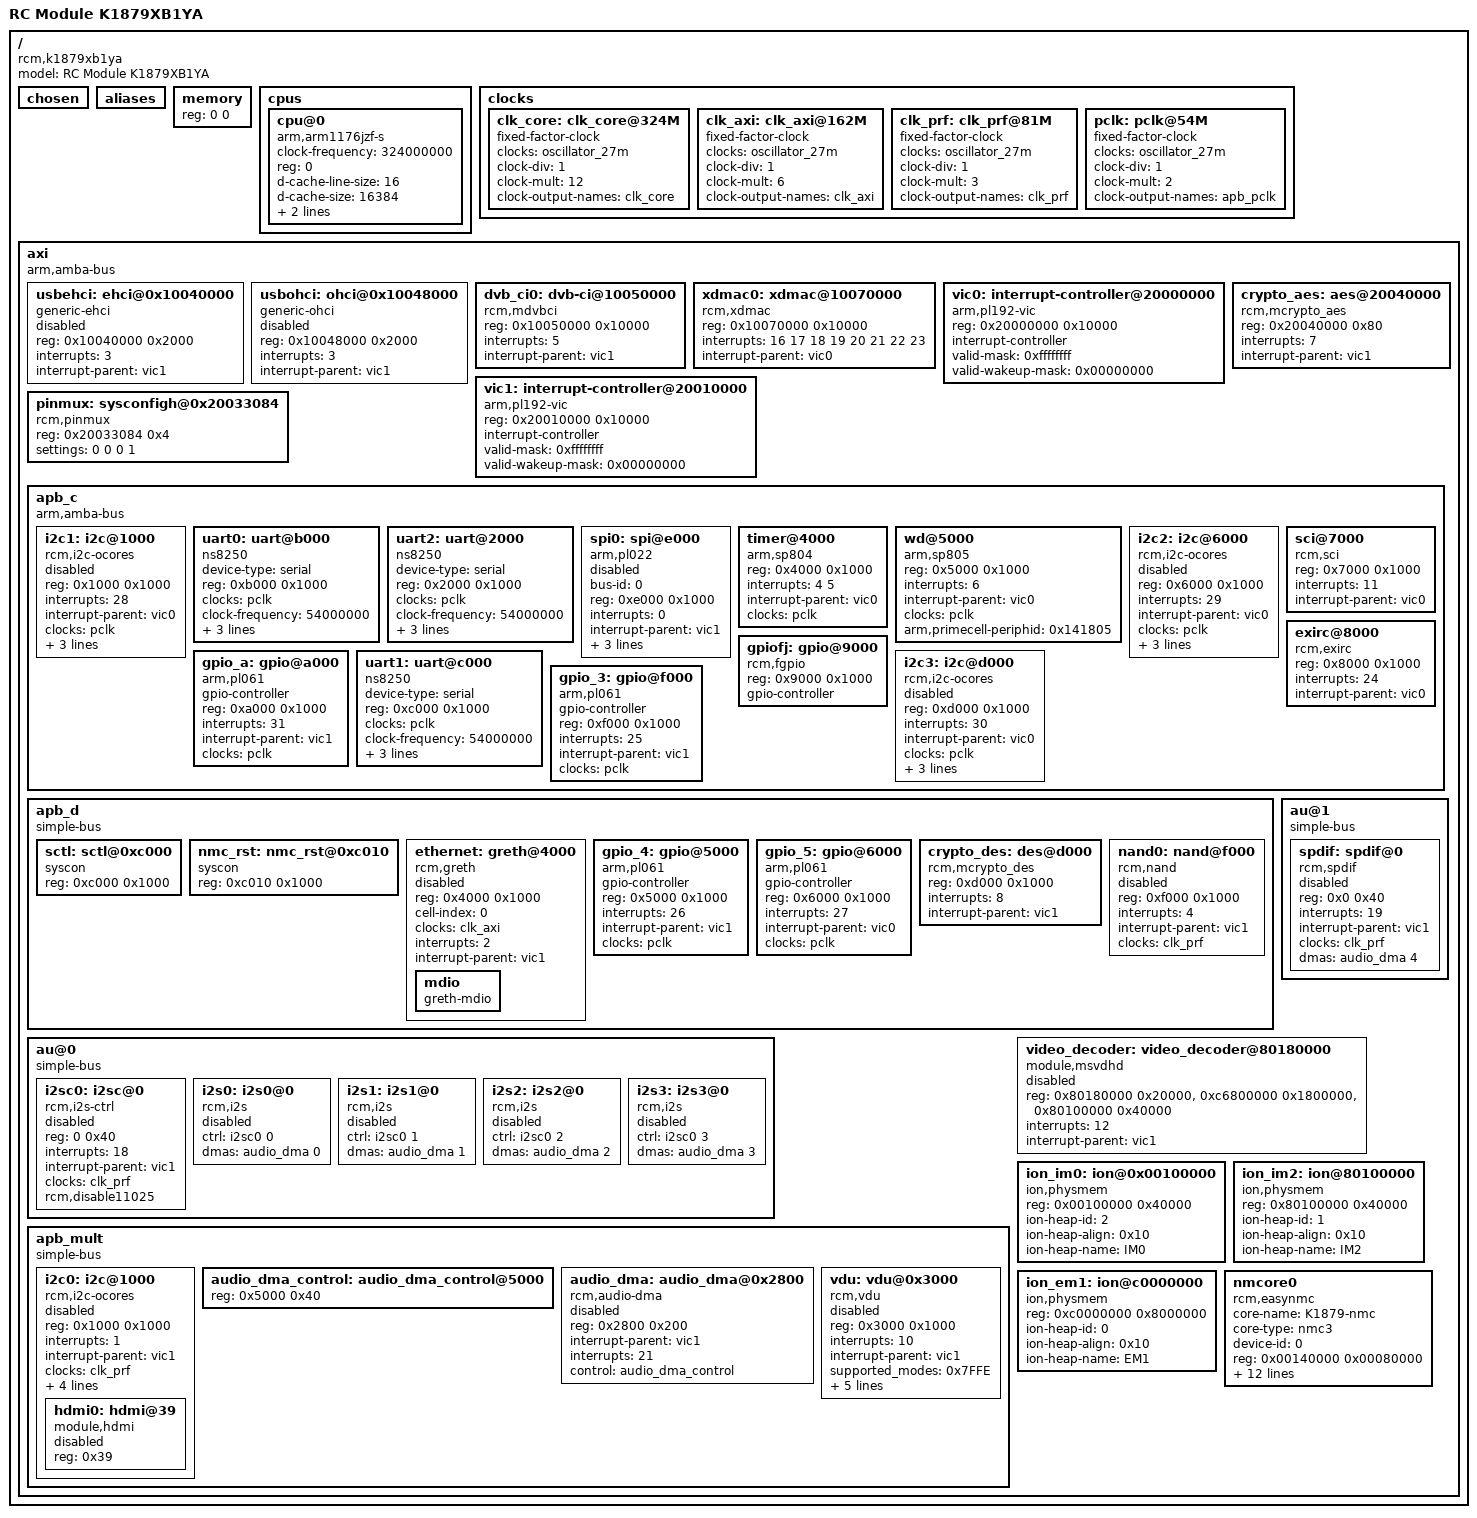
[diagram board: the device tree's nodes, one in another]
/*
 * Copyright Promwad inc 2011
 * Copyright RC Module 2010-2015
 *
 * Michail Kurachkin <stelhs@ya.ru>
 * Andrew Andrianov  <andrew@ncrmnt.org>
 *
 * This program is free software; you can redistribute it and/or modify
 * it under the terms of the GNU General Public License version 2 as
 * published by the Free Software Foundation.
 */

/ {

	model = "RC Module K1879XB1YA";
	compatible = "rcm,k1879xb1ya";

	#address-cells = <1>;
	#size-cells = <1>;
	chosen { };
	aliases { };
	memory { device_type = "memory"; reg = <0 0>; };

	cpus {
		#address-cells = <1>;
		#size-cells = <0>;
		cpu@0 {
			device_type = "cpu";
			compatible = "arm,arm1176jzf-s", "arm,arm1176";
			clock-frequency = <324000000>;
			reg = <0>;
			d-cache-line-size = <16>;
			d-cache-size = <16384>;
			i-cache-line-size = <16>;
			i-cache-size = <16384>;
		};
	};

	clocks {
			clk_core: clk_core@324M {
				/* Core 324MHz clock. */
				compatible = "fixed-factor-clock";
				#clock-cells = <0>;
				clocks = <&oscillator_27m>;
				clock-div = <1>;
				clock-mult = <12>;
				clock-output-names = "clk_core";
			};

			clk_axi: clk_axi@162M {
				/* 162MHz clock */
				compatible = "fixed-factor-clock";
				#clock-cells = <0>;
				clocks = <&oscillator_27m>;
				clock-div = <1>;
				clock-mult = <6>;
				clock-output-names = "clk_axi";
			};

			clk_prf: clk_prf@81M {
				/* 81MHz clock */
				compatible = "fixed-factor-clock";
				#clock-cells = <0>;
				clocks = <&oscillator_27m>;
				clock-div = <1>;
				clock-mult = <3>;
				clock-output-names = "clk_prf";
			};

			pclk: pclk@54M {
				/* Reference 54MHz clock */
				compatible = "fixed-factor-clock";
				#clock-cells = <0>;
				clocks = <&oscillator_27m>;
				clock-div = <1>;
				clock-mult = <2>;
				clock-output-names = "apb_pclk";
			};
	};

	axi {
		compatible = "arm,amba-bus";
		#address-cells = <1>;
		#size-cells = <1>;
		ranges = <0 0x0 0xFFFFFFFF>;

		usbehci: ehci@0x10040000 {
			compatible = "generic-ehci";
			reg = <0x10040000 0x2000>;
			interrupts = <3>; /* 35 */
			interrupt-parent = <&vic1>;
			status = "disabled";
		};

		usbohci: ohci@0x10048000 {
			compatible = "generic-ohci";
			reg = <0x10048000 0x2000>;
			interrupts = <3>; /* 35 */
			interrupt-parent = <&vic1>;
			status = "disabled";
		};

		dvb_ci0: dvb-ci@10050000 {
			compatible = "rcm,mdvbci";
			reg = <0x10050000 0x10000>;
			interrupts = <5>; /* 37 */
			interrupt-parent = <&vic1>;
		};

		xdmac0: xdmac@10070000 {
			compatible = "rcm,xdmac";
			reg = <0x10070000 0x10000>;
			interrupts = <16 17 18 19 20 21 22 23>;
			interrupt-parent = <&vic0>;
		};

		vic0: interrupt-controller@20000000 {
			reg = <0x20000000 0x10000>;
			compatible = "arm,pl192-vic";
			interrupt-controller;
			#interrupt-cells = <1>;
			valid-mask = <0xffffffff>;
			valid-wakeup-mask = <0x00000000>;
		};

		vic1: interrupt-controller@20010000 {
			reg = <0x20010000 0x10000>;
			compatible = "arm,pl192-vic";
			interrupt-controller;
			#interrupt-cells = <1>;
			valid-mask = <0xffffffff>;
			valid-wakeup-mask = <0x00000000>;
		};

		pinmux: sysconfigh@0x20033084 {
			compatible = "rcm,pinmux";
			reg = <0x20033084 0x4>;
			reg-names = "controlH";
			settings = <0 0 0 1>; // DVB, TS1, TS2, NAND; 0 = GPIO, 1 = peripheral
		};

		crypto_aes: aes@20040000 {
			compatible = "rcm,mcrypto_aes";
			reg = <0x20040000 0x80>;
			interrupts = <7>; /* 39 */
			interrupt-parent = <&vic1>;
		};

		apb_c {
			compatible = "arm,amba-bus", "simple-bus";
			#address-cells = <1>;
			#size-cells = <1>;
			ranges = <0 0x20020000 0x10000>;

			i2c1: i2c@1000 {
				#address-cells = <1>;
				#size-cells = <0>;
				reg = <0x1000 0x1000>;
				compatible = "rcm,i2c-ocores";
				interrupts = <28>;
				interrupt-parent = <&vic0>;
				clocks = <&pclk>;
				clock-names = "apb_pclk";
				clock-frequency = <54000000>;
				reg-shift = <2>;
				rcm-irq-fixup-id = <1>;
				status = "disabled";
			};

			uart0: uart@b000 {
				device-type = "serial";
				reg = <0xb000 0x1000>;
				compatible = "ns8250";
				clocks = <&pclk>;
				clock-names = "apb_pclk";
				clock-frequency = <54000000>;
				interrupts = <7>;
				interrupt-parent = <&vic0>;
				reg-shift = <2>;
			};

			uart2: uart@2000 {
				device-type = "serial";
				reg = <0x2000 0x1000>;
				compatible = "ns8250";
				clocks = <&pclk>;
				clock-names = "apb_pclk";
				clock-frequency = <54000000>;
				interrupts = <9>;
				interrupt-parent = <&vic0>;
				reg-shift = <2>;
			};

			spi0: spi@e000 {
				compatible = "arm,pl022", "arm,primecell";
				bus-id = <0>;
				reg = <0xe000 0x1000>;
				#address-cells = <1>;
				#size-cells = <0>;
				interrupts = <0>; /* 32 */
				interrupt-parent = <&vic1>;
				clocks = <&pclk>;
				clock-names = "apb_pclk";
				num-cs = <2>;
				status = "disabled";
				/* Silicon BUG: no periphid at 0xe000 reg */
				arm,primecell-periphid = <0x41022>;
			};

			timer@4000 {
				compatible = "arm,sp804", "arm,primecell";
				reg = <0x4000 0x1000>;
				interrupts = <4 5>;
				interrupt-parent = <&vic0>;
				interrupt-names = "timer0", "timer1";
				clocks = <&pclk>;
				clock-names = "apb_pclk";
			};

			wd@5000 {
				reg = <0x5000 0x1000>;
				compatible = "arm,sp805", "arm,primecell";
				interrupts = <6>;
				interrupt-parent = <&vic0>;
				clocks = <&pclk>;
				clock-names = "apb_pclk";
				arm,primecell-periphid = <0x141805>;
				status = "okay";
			};

			i2c2: i2c@6000 {
				#address-cells = <1>;
				#size-cells = <0>;
				reg = <0x6000 0x1000>;
				compatible = "rcm,i2c-ocores";
				interrupts = <29>;
				interrupt-parent = <&vic0>;
				clocks = <&pclk>;
				clock-names = "apb_pclk";
				clock-frequency = <54000000>;
				reg-shift = <2>;
				rcm-irq-fixup-id = <2>;
				status = "disabled";
			};

			sci@7000 {
				reg = <0x7000 0x1000>;
				compatible = "rcm,sci";
				interrupts = <11>;
				interrupt-parent = <&vic0>;
			};

			exirc@8000 {
				reg = <0x8000 0x1000>;
				compatible = "rcm,exirc";
				interrupts = <24>;
				interrupt-parent = <&vic0>;
			};

			gpiofj: gpio@9000 {
				#gpio-cells = <2>;
				reg = <0x9000 0x1000>;
				reg-names = "regs";
				gpio-controller;
				compatible = "rcm,fgpio";
			};

			gpio_a: gpio@a000 {
				#gpio-cells = <2>;
				compatible = "arm,pl061", "arm,primecell";
				gpio-controller;
				reg = <0xa000 0x1000>;
				interrupts = <31>; /* 63 */
				interrupt-parent = <&vic1>;
				clocks = <&pclk>;
				clock-names = "apb_pclk";
			};

			uart1: uart@c000 {
				device-type = "serial";
				reg = <0xc000 0x1000>;
				compatible = "ns8250";
				clocks = <&pclk>;
				clock-names = "apb_pclk";
				clock-frequency = <54000000>;
				interrupts = <8>;
				interrupt-parent = <&vic0>;
				reg-shift = <2>;
			};

			i2c3: i2c@d000 {
				#address-cells = <1>;
				#size-cells = <0>;
				reg = <0xd000 0x1000>;
				compatible = "rcm,i2c-ocores";
				interrupts = <30>;
				interrupt-parent = <&vic0>;
				clocks = <&pclk>;
				clock-names = "apb_pclk";
				clock-frequency = <54000000>;
				reg-shift = <2>;
				rcm-irq-fixup-id = <3>;
				status = "disabled";
			};

			gpio_3: gpio@f000 {
				#gpio-cells = <2>;
				compatible = "arm,pl061", "arm,primecell";
				gpio-controller;
				reg = <0xf000 0x1000>;
				interrupts = <25>; /* 57 */
				interrupt-parent = <&vic1>;
				clocks = <&pclk>;
				clock-names = "apb_pclk";
			};
		};

		apb_d {
			compatible = "simple-bus";
			#address-cells = <1>;
			#size-cells = <1>;
			ranges = <0 0x20030000 0x10000>;

			sctl: sctl@0xc000
			{
				compatible = "syscon";
				reg = <0xc000 0x1000>;
			};

			nmc_rst: nmc_rst@0xc010
			{
				compatible = "syscon";
				reg = <0xc010 0x1000>;
			};

			ethernet: greth@4000 {
				#address-cells = <1>;
				#size-cells = <1>;
				compatible = "rcm,greth";
				reg = <0x4000 0x1000>;
				cell-index = <0>;
				device_type = "network";
				clocks = <&clk_axi>;
				clock-names = "clk_axi";
				interrupts = <2>; /* 34 */
				interrupt-parent = <&vic1>;
				status = "disabled";

				mdio {
					compatible = "greth-mdio";
					#address-cells = <1>;
					#size-cells = <0>;
				};
			};

			gpio_4: gpio@5000 {
				#gpio-cells = <2>;
				compatible = "arm,pl061", "arm,primecell";
				gpio-controller;
				reg = <0x5000 0x1000>;
				interrupts = <26>; /* 58 */
				interrupt-parent = <&vic1>;
				clocks = <&pclk>;
				clock-names = "apb_pclk";
			};

			gpio_5: gpio@6000 {
				#gpio-cells = <2>;
				compatible = "arm,pl061", "arm,primecell";
				gpio-controller;
				reg = <0x6000 0x1000>;
				interrupts = <27>;
				interrupt-parent = <&vic0>;
				clocks = <&pclk>;
				clock-names = "apb_pclk";
			};

			crypto_des: des@d000 {
				compatible = "rcm,mcrypto_des";
				reg = <0xd000 0x1000>;
				interrupts = <8>; /* 40 */
				interrupt-parent = <&vic1>;
			};

			nand0: nand@f000 {
				reg = <0xf000 0x1000>;
				compatible = "rcm,nand";
				interrupts = <4>; /* 36 */
				interrupt-parent = <&vic1>;
				clocks = <&clk_prf>;
				clock-names = "clk_prf";
				status = "disabled";
			};
		};

		au@0 {
			compatible = "simple-bus";
			#address-cells = <1>;
			#size-cells = <1>;
			ranges = <0 0x80150000 0x10000>;

			i2sc0: i2sc@0 {
				status = "disabled";
				compatible = "rcm,i2s-ctrl";
				#i2s-cells = <1>;
				reg = <0 0x40>;
				interrupts = <18>; // 50
				interrupt-parent = <&vic1>;
				clocks = <&clk_prf>;
				rcm,disable11025; // ??
			};

			i2s0: i2s0@0 {
				status = "disabled";
				compatible = "rcm,i2s";
				#sound-dai-cells = <0>;
				ctrl = <&i2sc0 0>;
				dmas = <&audio_dma 0>;
				dma-names = "rx";
			};

			i2s1: i2s1@0 {
				status = "disabled";
				compatible = "rcm,i2s";
				#sound-dai-cells = <0>;
				ctrl = <&i2sc0 1>;
				dmas = <&audio_dma 1>;
				dma-names = "rx";
			};

			i2s2: i2s2@0 {
				status = "disabled";
				compatible = "rcm,i2s";
				#sound-dai-cells = <0>;
				ctrl = <&i2sc0 2>;
				dmas = <&audio_dma 2>;
				dma-names = "rx";
			};

			i2s3: i2s3@0 {
				status = "disabled";
				compatible = "rcm,i2s";
				#sound-dai-cells = <0>;
				ctrl = <&i2sc0 3>;
				dmas = <&audio_dma 3>;
				dma-names = "rx";
			};

			//i2s: i2s@0 {
			//	compatible = "module,i2s";
			//	reg = <0 0x40>;
			//	interrupts = <18>; /* 50 */
			//	interrupt-parent = <&vic1>;
			//};
		};

		au@1 {
			compatible = "simple-bus";
			#address-cells = <1>;
			#size-cells = <1>;
			ranges = <0x0 0x80160000 0x10000>;

			spdif: spdif@0 {
				status = "disabled";
				compatible = "rcm,spdif";
				reg = <0x0 0x40>;
				interrupts = <19>; // 51
				#sound-dai-cells = <0>;
				interrupt-parent = <&vic1>;
				clocks = <&clk_prf>;//???????????
				dmas = <&audio_dma 4>;
				dma-names = "rx";
			};

			//spdif: spdif@0 {
			//	compatible = "module,spdif";
			//	reg = <0x0 0x40>;
			//	interrupts = <19>; /* 51 */
			//	interrupt-parent = <&vic1>;
			//};
		};

		apb_mult {
			compatible = "simple-bus";
			#address-cells = <1>;
			#size-cells = <1>;
			ranges = <0 0x80170000 0x10000>;

			i2c0: i2c@1000 {
				#address-cells = <1>;
				#size-cells = <0>;
				reg = <0x1000 0x1000>;
				compatible = "rcm,i2c-ocores";
				interrupts = <1>; /* 33 */
				interrupt-parent = <&vic1>;
				clocks = <&clk_prf>;
				clock-names = "clk_prf";
				clock-frequency = <81000000>; // <54000000>
				speed = <100000>;
				reg-shift = <2>;
				rcm-irq-fixup-id = <0>;
				status = "disabled";
				hdmi0: hdmi@39 {
					compatible = "module,hdmi";
					reg = <0x39>;
					status = "disabled";
				};
			};

			audio_dma_control: audio_dma_control@5000 {
				reg = <0x5000 0x40>; /* control */
			};

			audio_dma: audio_dma@0x2800 {
				status = "disabled";
				compatible = "rcm,audio-dma";
				reg = <0x2800 0x200>;					// <0x38017000 0x1000>;
				#dma-cells = <1>;
				interrupt-parent = <&vic1>;				// <&MPIC>;
				interrupts = <21>;						// <127 0>;
				control = <&audio_dma_control>;
			};

			//dmac: dmac@0x2800 {
			//	compatible = "module,dmac";
			//	reg = <0x2800 0x200>;
			//	interrupts = <21>; /* 53 */
			//	interrupt-parent = <&vic1>;
			//};

			vdu: vdu@0x3000 {
				#address-cells = <1>;
				#size-cells = <1>;
				compatible = "rcm,vdu";
				reg = <0x3000 0x1000>;
				interrupts = <10>; /* 42 */
				interrupt-parent = <&vic1>;
				supported_modes = <0x7FFE>;
				default_mode = <0x4>;
				output_flags = <0x200>;
				axi_osd_param = <0x0f310000>;
				axi_mvl_param = <0x0f310000>;
				vdubuffer = <0xc0000000 0x2000000>; /* 32MB  EM1 !*/
				status = "disabled";
			};
		};

		//sound: audio@0x80175000 {
		//	compatible = "module,audio";
		//	reg = <0x80175000 0x40>; /* control */
		//	interrupts = <21>; /* 53 */
		//	interrupt-parent = <&vic1>;
		//	maudio,dmac = <&dmac>;
		//	maudio,i2s = <&i2s>;
		//	maudio,spdif = <&spdif>;
		//	status = "disabled";
		//};

		video_decoder: video_decoder@80180000 {
			compatible = "module,msvdhd";
			reg = <0x80180000 0x20000>,
					<0xc6800000 0x1800000>, /* EM1! */
					<0x80100000 0x40000>;
			reg-names = "registers", "extmem", "intmem";
			interrupts = <12>; /* 44 */
			interrupt-parent = <&vic1>;
			interrupt-names = "irq";
			status = "disabled";
		};


		ion_im0: ion@0x00100000 {
		     compatible = "ion,physmem";
		     reg = <0x00100000 0x40000>;
		     reg-names = "memory";
		     ion-heap-id   = <2>;
		     //ion-heap-type = <ION_HEAP_TYPE_DMA>;
		     ion-heap-align = <0x10>;
		     ion-heap-name = "IM0";
		};

		ion_im2: ion@80100000 {
		     compatible = "ion,physmem";
		     reg = <0x80100000 0x40000>;
		     reg-names = "memory";
		     ion-heap-id   = <1>;
		    // ion-heap-type = <ION_HEAP_TYPE_DMA>;
		     ion-heap-align = <0x10>;
		     ion-heap-name = "IM2";
		};

		ion_em1: ion@c0000000 {
		     compatible = "ion,physmem";
		     reg = <0xc0000000 0x8000000>;
		     reg-names = "memory";
		     ion-heap-id   = <0>;
		     //ion-heap-type = <ION_HEAP_TYPE_DMA>;
		     ion-heap-align = <0x10>;
		     ion-heap-name = "EM1";
		};

		nmcore0 {
			compatible = "rcm,easynmc";
			core-name = "K1879-nmc";
			core-type = "nmc3";
			device-id = <0>;
			reg = <0x00140000 0x00080000>; /* IM1 + IM3 */
			reg-names = "imem";
			bank-count = <2>;

			memory-region = <&nmc_mem0>;

			control = <&sctl>;
			reset = <&nmc_rst>;

			reset_bit =     <0>; // reset bit no
			//lp_status_reg = <?>, <?>;
			//hp_status_reg = <?>, <?>;
			lp_set_reg = <0x3C>, <0>;
			hp_set_reg = <0x38>, <0>;
			nmi_set_reg = <0x04>, <0>;
			hp_clr_reg = <0x34>, <0>;
			lp_clr_reg = <0x30>, <0>;

			interrupts = <14>, <15>;
			interrupt-parent = <&vic0>;
			interrupt-names = "hp", "lp";
			status = "okay";
		};

	};
};
